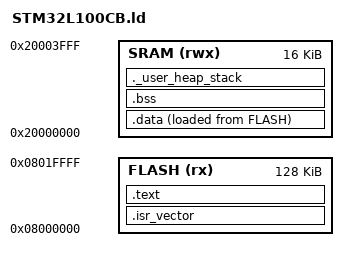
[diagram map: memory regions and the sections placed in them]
/* STM32L100CB linker script: 128KB Flash, 16KB SRAM */
MEMORY
{
    FLASH (rx)  : ORIGIN = 0x08000000, LENGTH = 128K
    SRAM  (rwx) : ORIGIN = 0x20000000, LENGTH = 16K
}

_estack = ORIGIN(SRAM) + LENGTH(SRAM);
_Min_Heap_Size = 0;
_Min_Stack_Size = 0x800;

SECTIONS
{
    .isr_vector :
    {
        . = ALIGN(4);
        KEEP(*(.isr_vector))
        . = ALIGN(4);
    } >FLASH

    .text :
    {
        . = ALIGN(4);
        *(.text)
        *(.text*)
        *(.rodata)
        *(.rodata*)
        KEEP(*(.init))
        KEEP(*(.fini))
        . = ALIGN(4);
        _etext = .;
    } >FLASH

    _sidata = LOADADDR(.data);

    .data :
    {
        . = ALIGN(4);
        _sdata = .;
        *(.data)
        *(.data*)
        . = ALIGN(4);
        _edata = .;
    } >SRAM AT> FLASH

    .bss :
    {
        . = ALIGN(4);
        _sbss = .;
        __bss_start__ = _sbss;
        *(.bss)
        *(.bss*)
        *(COMMON)
        . = ALIGN(4);
        _ebss = .;
        __bss_end__ = _ebss;
    } >SRAM

    ._user_heap_stack :
    {
        . = ALIGN(8);
        PROVIDE(end = .);
        PROVIDE(_end = .);
        . = . + _Min_Heap_Size;
        . = . + _Min_Stack_Size;
        . = ALIGN(8);
    } >SRAM
}
